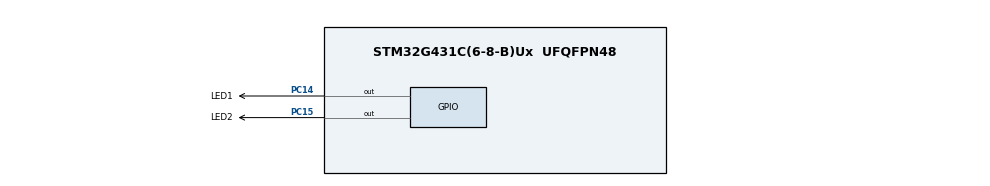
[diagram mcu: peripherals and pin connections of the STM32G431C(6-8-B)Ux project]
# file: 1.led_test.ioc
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Mcu.Family=STM32G4
Mcu.Name=STM32G431C(6-8-B)Ux
Mcu.Package=UFQFPN48
NVIC.PriorityGroup=NVIC_PRIORITYGROUP_4
PA13.Mode=Serial_Wire
PA13.Signal=SYS_JTMS-SWDIO
PA14.Mode=Serial_Wire
PA14.Signal=SYS_JTCK-SWCLK
PC14-OSC32_IN.GPIO_Label=LED1
PC14-OSC32_IN.PinState=GPIO_PIN_SET
PC14-OSC32_IN.Signal=GPIO_Output
PC15-OSC32_OUT.GPIO_Label=LED2
PC15-OSC32_OUT.PinState=GPIO_PIN_SET
PC15-OSC32_OUT.Signal=GPIO_Output
PF0-OSC_IN.Mode=HSE-External-Oscillator
PF0-OSC_IN.Signal=RCC_OSC_IN
PF1-OSC_OUT.Mode=HSE-External-Oscillator
PF1-OSC_OUT.Signal=RCC_OSC_OUT
ProjectManager.HeapSize=0x200
ProjectManager.StackSize=0x400
ProjectManager.TargetToolchain=MDK-ARM V5.32
RCC.ADC12Freq_Value=170000000
RCC.AHBFreq_Value=170000000
RCC.APB1Freq_Value=170000000
RCC.APB1TimFreq_Value=170000000
RCC.APB2Freq_Value=170000000
RCC.APB2TimFreq_Value=170000000
RCC.CortexFreq_Value=170000000
RCC.EXTERNAL_CLOCK_VALUE=12288000
RCC.HCLKFreq_Value=170000000
RCC.HSE_VALUE=24000000
RCC.HSI48_VALUE=48000000
RCC.HSI_VALUE=16000000
RCC.LSE_VALUE=32768
RCC.PLLM=RCC_PLLM_DIV6
RCC.PLLN=85
RCC.PLLSourceVirtual=RCC_PLLSOURCE_HSE
RCC.SYSCLKFreq_VALUE=170000000
RCC.SYSCLKSource=RCC_SYSCLKSOURCE_PLLCLK
RCC.USBFreq_Value=170000000
RCC.VCOOutputFreq_Value=340000000
VP_SYS_VS_DBSignals.Mode=DisableDeadBatterySignals
board=custom

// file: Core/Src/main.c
/* USER CODE BEGIN Header */
/**
 ******************************************************************************
 * @file           : main.c
 * @brief          : Main program body
 ******************************************************************************
 * @attention
 *
 * Copyright (c) 2024 STMicroelectronics.
 * All rights reserved.
 *
 * This software is licensed under terms that can be found in the LICENSE file
 * in the root directory of this software component.
 * If no LICENSE file comes with this software, it is provided AS-IS.
 *
 ******************************************************************************
 */
/* USER CODE END Header */
#include "main.h"
#include "gpio.h"

void SystemClock_Config(void);

int main(void)
{

  /* MCU Configuration--------------------------------------------------------*/

  /* Reset of all peripherals, Initializes the Flash interface and the Systick. */
  LL_APB2_GRP1_EnableClock(LL_APB2_GRP1_PERIPH_SYSCFG);
  LL_APB1_GRP1_EnableClock(LL_APB1_GRP1_PERIPH_PWR);

  /* System interrupt init*/
  NVIC_SetPriorityGrouping(NVIC_PRIORITYGROUP_4);

  /* SysTick_IRQn interrupt configuration */
  NVIC_SetPriority(SysTick_IRQn, NVIC_EncodePriority(NVIC_GetPriorityGrouping(), 15, 0));

  /** Disable the internal Pull-Up in Dead Battery pins of UCPD peripheral
   */
  LL_PWR_DisableUCPDDeadBattery();

  /* Configure the system clock */
  SystemClock_Config();

  /* Initialize all configured peripherals */
  MX_GPIO_Init();

  /* Infinite loop */
  /* USER CODE BEGIN WHILE */
  while (1)
  {
    LL_GPIO_TogglePin(LED1_GPIO_Port, LED1_Pin);
    LL_mDelay(100);
    LL_GPIO_TogglePin(LED2_GPIO_Port, LED2_Pin);
    LL_mDelay(100);
    /* USER CODE END WHILE */

  }
}

void SystemClock_Config(void)
{
  LL_FLASH_SetLatency(LL_FLASH_LATENCY_4);
  while (LL_FLASH_GetLatency() != LL_FLASH_LATENCY_4)
  {
  }
  LL_PWR_EnableRange1BoostMode();
  LL_RCC_HSE_Enable();
  /* Wait till HSE is ready */
  while (LL_RCC_HSE_IsReady() != 1)
  {
  }

  LL_RCC_PLL_ConfigDomain_SYS(LL_RCC_PLLSOURCE_HSE, LL_RCC_PLLM_DIV_6, 85, LL_RCC_PLLR_DIV_2);
  LL_RCC_PLL_EnableDomain_SYS();
  LL_RCC_PLL_Enable();
  /* Wait till PLL is ready */
  while (LL_RCC_PLL_IsReady() != 1)
  {
  }

  LL_RCC_SetSysClkSource(LL_RCC_SYS_CLKSOURCE_PLL);
  LL_RCC_SetAHBPrescaler(LL_RCC_SYSCLK_DIV_2);
  /* Wait till System clock is ready */
  while (LL_RCC_GetSysClkSource() != LL_RCC_SYS_CLKSOURCE_STATUS_PLL)
  {
  }

  /* Insure 1us transition state at intermediate medium speed clock*/
  for (__IO uint32_t i = (170 >> 1); i != 0; i--)
    ;

  /* Set AHB prescaler*/
  LL_RCC_SetAHBPrescaler(LL_RCC_SYSCLK_DIV_1);
  LL_RCC_SetAPB1Prescaler(LL_RCC_APB1_DIV_1);
  LL_RCC_SetAPB2Prescaler(LL_RCC_APB2_DIV_1);

  LL_Init1msTick(170000000);

  LL_SetSystemCoreClock(170000000);
}

void Error_Handler(void)
{
  __disable_irq();
  while (1)
  {
  }
}
